VERSION ""

NS_ :

BS_:
BU_:
BO_ 133 GearStatus: 8 Vector__XXX
   SG_ GearPosition : 15|8@0+ (1,0) [0|1] "" Vector__XXX
   SG_ GearStatusSpeed : 39|16@0+ (1,0) [0|1] "" Vector__XXX

BO_ 139 Unknown: 8 Vector__XXX
   SG_ WheelSpeed1 : 7|16@0+ (1,0) [0|1] "" Vector__XXX
   SG_ WheelSpeed2 : 23|16@0+ (1,0) [0|1] "" Vector__XXX
   SG_ WheelSpeed3 : 39|16@0+ (1,0) [0|1] "" Vector__XXX
   SG_ WheelSpeed4 : 55|16@0+ (1,0) [0|1] "" Vector__XXX

BO_ 122 IgnitionSwitch: 4 Vector__XXX
   SG_ IgnitionSwitchPos : 15|8@0+ (1,0) [0|1] "" Vector__XXX

BO_ 1100 Config6: 8 Vector__XXX
   SG_ Config6 : 7|64@0+ (1,0) [0|1] "" Vector__XXX

BO_ 1098 Config5: 8 Vector__XXX
   SG_ Config5 : 7|64@0+ (1,0) [0|1] "" Vector__XXX

BO_ 992 VIN: 8 Vector__XXX
   SG_ VIN : 15|64@4- (1,0) [0|1] "" Vector__XXX
   SG_ VIN_MsgNo : 7|8@0+ (1,0) [0|1] "" Vector__XXX

BO_ 881 SwayBar: 8 Vector__XXX
   SG_ SwayBarDisconnected : 8|1@0+ (1,0) [0|1] "" Vector__XXX
   SG_ SwayBarInProgress : 9|1@0+ (1,0) [0|1] "" Vector__XXX
   SG_ SwayBarLocked : 0|1@0+ (1,0) [0|1] "" Vector__XXX
   SG_ SwayBarPosition : 7|4@0+ (1,0) [0|1] "" Vector__XXX

BO_ 848 DateTime: 8 Vector__XXX
   SG_ DateTimeSeconds : 7|8@0+ (1,0) [0|1] "" Vector__XXX
   SG_ DateTimeMinutes : 15|8@0+ (1,0) [0|1] "" Vector__XXX
   SG_ DateTimeHours : 23|8@0+ (1,0) [0|1] "" Vector__XXX
   SG_ DateTimeYear : 31|16@0+ (1,0) [0|1] "" Vector__XXX
   SG_ DateTimeMonth : 47|8@0+ (1,0) [0|1] "" Vector__XXX
   SG_ DateTimeDay : 55|8@0+ (1,0) [0|1] "" Vector__XXX

BO_ 808 MusicInfo: 8 Vector__XXX

BO_ 662 TirePressure: 8 Vector__XXX
   SG_ TirePressureLF : 31|8@0+ (1,0) [0|1] "psi" Vector__XXX
   SG_ TirePressureRF : 39|8@0+ (1,0) [0|1] "psi" Vector__XXX
   SG_ TirePressureLR : 47|8@0+ (1,0) [0|1] "psi" Vector__XXX
   SG_ TirePressureRR : 55|8@0+ (1,0) [0|1] "psi" Vector__XXX

BO_ 295 Temperatures2: 8 Vector__XXX
   SG_ AmbientPressure : 23|8@0+ (1,0) [0|1] "kPa" Vector__XXX
   SG_ IAT : 7|8@0+ (1,-40) [0|1] "C" Vector__XXX
   SG_ ECT : 15|8@0+ (1,-40) [0|1] "C" Vector__XXX

BO_ 2147483795 GearPosition: 8 Vector__XXX
   SG_ GearPositionSig278 : 23|8@4- (1,0) [0|1] "" Vector__XXX

BO_ 2147484031 GPSSpeed: 8 Vector__XXX
   SG_ GPSSpeed : 55|16@0+ (1,0) [0|1] "" Vector__XXX

BO_ 2147483683 SteeringWheel: 8 Vector__XXX
   SG_ WheelAngle : 7|16@0+ (0.0350877,-144) [0|1] "degrees" Vector__XXX
   SG_ SteeringWheeRateOfChange : 23|16@0+ (1,-4096) [0|1] "" Vector__XXX

BO_ 2147484556 DateTime2: 8 Vector__XXX
   SG_ DateTime2Seconds : 63|8@0+ (1,0) [0|1] "" Vector__XXX

BO_ 2147483691 Accelerometer: 8 Vector__XXX
   SG_ AccelerationLat : 7|16@0+ (1,-2048) [0|1] "" Vector__XXX
   SG_ AccelerationLong : 23|16@0+ (1,-2048) [0|1] "" Vector__XXX
   SG_ YawRate : 39|16@0+ (1,-2048) [0|1] "" Vector__XXX

BO_ 2147483783 Brake: 8 Vector__XXX
   SG_ BrakePressure : 7|16@0+ (1,0) [0|1] "" Vector__XXX

BO_ 2147483769 Brake2: 8 Vector__XXX
   SG_ Brake2Pressure1 : 6|15@0+ (1,0) [0|1] "" Vector__XXX
   SG_ Brake2Pressure2 : 23|16@0+ (1,0) [0|1] "" Vector__XXX
   SG_ Brake2VehicleStopped : 7|1@0+ (1,0) [0|1] "" Vector__XXX

BO_ 2147483779 Speed1: 8 Vector__XXX
   SG_ Speed1Speed : 37|14@0+ (0.5,0) [0|1] "kph" Vector__XXX

BO_ 2147483687 Unknown027: 8 Vector__XXX
   SG_ PossibleMAFFreq : 3|12@0+ (1,0) [0|1] "" Vector__XXX
   SG_ Unknown027Sig3277 : 23|16@0+ (1,-1900) [0|1] "" Vector__XXX

BO_ 2147483793 Constant: 8 Vector__XXX

BO_ 2147483685 Unknown: 8 Vector__XXX
   SG_ Rpm : 7|16@0+ (1,0) [0|1] "" Vector__XXX
   SG_ UnknownRpmRelated : 23|16@0+ (1,0) [0|1] "" Vector__XXX
   SG_ UnknownRpmRelated2 : 39|16@0+ (1,0) [0|1] "" Vector__XXX

BO_ 2147483695 Unknown: 8 Vector__XXX
   SG_ UnknownSig339 : 39|16@0+ (1,0) [0|1] "" Vector__XXX

BO_ 2147483701 Unknown: 8 Vector__XXX
   SG_ UnknownSig93 : 7|16@0- (1,0) [0|1] "" Vector__XXX
   SG_ UnknownSig9343 : 23|16@0+ (1,0) [0|1] "" Vector__XXX
   SG_ UnknownSig934314 : 39|16@0+ (1,0) [0|1] "" Vector__XXX

BO_ 2147483703 Unknown: 8 Vector__XXX
   SG_ UnknownSig278 : 7|16@0+ (1,0) [0|1] "" Vector__XXX
   SG_ UnknownSig27840 : 39|16@0+ (1,0) [0|1] "" Vector__XXX

BO_ 2147483761 Unknown: 8 Vector__XXX
   SG_ UnknownSig297 : 7|16@0+ (1,0) [0|1] "" Vector__XXX

BO_ 2147483767 IgnitionStatus: 2 Vector__XXX
   SG_ IgnitionSwitch : 7|8@0+ (1,0) [0|1] "" Vector__XXX
   SG_ IgnitionState : 15|8@0+ (1,0) [0|1] "" Vector__XXX

BO_ 2147483771 Unknown: 8 Vector__XXX
   SG_ UnknownSig84 : 7|16@0+ (1,0) [0|1] "" Vector__XXX
   SG_ UnknownSig8455 : 23|16@0+ (1,0) [0|1] "" Vector__XXX
   SG_ UnknownSig845598 : 39|16@0+ (1,0) [0|1] "" Vector__XXX

BO_ 2147483777 Unknown: 8 Vector__XXX
   SG_ UnknownSig164 : 23|8@0+ (1,0) [0|1] "" Vector__XXX
   SG_ UnknownSig16496 : 39|8@0+ (1,0) [0|1] "" Vector__XXX
   SG_ UnknownSig1649643 : 47|8@0+ (1,0) [0|1] "" Vector__XXX

BO_ 2147483785 Unknown: 8 Vector__XXX
   SG_ UnknownSig75 : 7|16@0+ (1,0) [0|1] "" Vector__XXX
   SG_ UnknownSig7590 : 23|16@0+ (1,0) [0|1] "" Vector__XXX
   SG_ UnknownSig759080 : 39|16@0+ (1,0) [0|1] "" Vector__XXX

BO_ 2147483797 Unknown: 8 Vector__XXX
   SG_ UnknownSig456 : 7|16@0+ (1,0) [0|1] "" Vector__XXX

BO_ 2147483801 Unknown: 8 Vector__XXX
   SG_ UnknownSig401 : 7|16@0+ (1,0) [0|1] "" Vector__XXX

BO_ 2147483819 Unknown: 8 Vector__XXX
   SG_ UnknownSig131 : 23|8@0+ (1,0) [0|1] "" Vector__XXX
   SG_ UnknownSig13192 : 31|8@0+ (1,0) [0|1] "" Vector__XXX

BO_ 2147483821 Transmission: 4 Vector__XXX
   SG_ TransmissionSig181 : 3|4@0+ (1,0) [0|1] "" Vector__XXX

BO_ 2147483827 Speed: 8 Vector__XXX
   SG_ Speed : 23|16@0+ (1,0) [0|1] "" Vector__XXX
   SG_ UnknownSig46360 : 39|16@0+ (1,0) [0|1] "" Vector__XXX

BO_ 2147483829 Rpm: 8 Vector__XXX
   SG_ Rpm : 23|16@0+ (1,0) [0|1] "" Vector__XXX

BO_ 2147483869 AxleDistance: 8 Vector__XXX
   SG_ DistanceFrontAxle : 7|16@0+ (1,0) [0|1] "" Vector__XXX
   SG_ DistanceRearAxle : 23|16@0+ (1,0) [0|1] "" Vector__XXX

BO_ 2147483953 ECUCode: 8 Vector__XXX

BO_ 2147483965 Unknown: 8 Vector__XXX
   SG_ Temperature : 31|8@0+ (1,0) [0|1] "" Vector__XXX
   SG_ Unknown : 39|16@0+ (1,0) [0|1] "" Vector__XXX

BO_ 2147483971 Empty: 8 Vector__XXX

BO_ 2147483982 Unknown: 8 Vector__XXX
   SG_ UnknownSig15 : 7|16@0+ (1,0) [0|1] "" Vector__XXX

BO_ 2147483989 Empty: 8 Vector__XXX

BO_ 2147483991 Constant: 8 Vector__XXX

BO_ 2147483993 Empty: 8 Vector__XXX

BO_ 2147484096 Constant: 8 Vector__XXX

BO_ 2147484112 Toggle: 8 Vector__XXX

BO_ 2147484117 Constant: 8 Vector__XXX

BO_ 2147484137 Constant: 8 Vector__XXX

BO_ 2147484139 Empty: 8 Vector__XXX

BO_ 2147484150 Constant: 8 Vector__XXX

BO_ 2147484151 Unknown: 8 Vector__XXX
   SG_ SpeedMPHLowRes : 55|16@0+ (1,0) [0|1] "mph" Vector__XXX

BO_ 2147484208 Temperature: 8 Vector__XXX

BO_ 2147484232 Constant: 8 Vector__XXX

BO_ 2147484277 Constant: 8 Vector__XXX

BO_ 2147484249 StartButton: 8 Vector__XXX

BO_ 2147484257 Counter: 8 Vector__XXX

BO_ 2147484261 Constant: 8 Vector__XXX

BO_ 2147484271 SwayBarRequest: 8 Vector__XXX
   SG_ UnknownSig221 : 31|16@0+ (1,0) [0|1] "" Vector__XXX
   SG_ SwayBarRequest : 14|1@0+ (1,0) [0|1] "" Vector__XXX

BO_ 2147484333 Constant: 8 Vector__XXX

BO_ 2147484338 Constant: 8 Vector__XXX

BO_ 2147484357 Constant: 8 Vector__XXX

BO_ 2147484358 Constant: 8 Vector__XXX

BO_ 2147484359 Constant: 8 Vector__XXX

BO_ 2147484360 Constant: 8 Vector__XXX

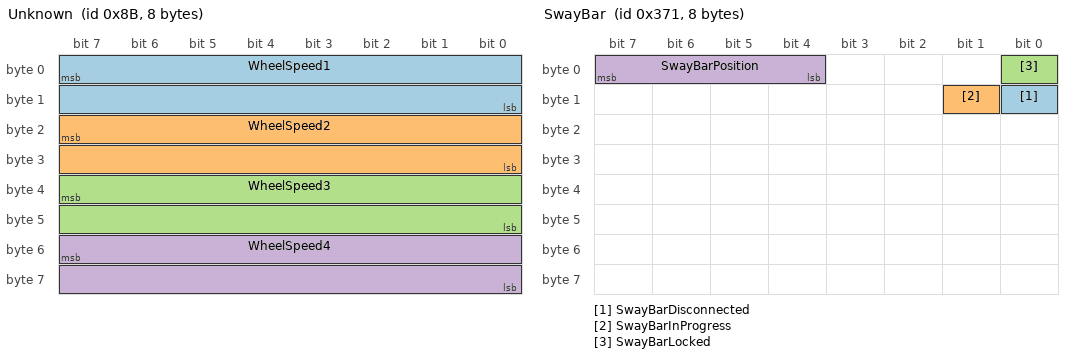
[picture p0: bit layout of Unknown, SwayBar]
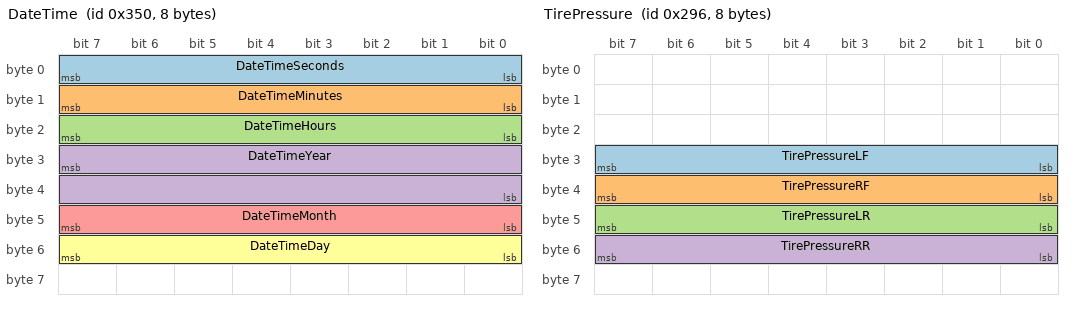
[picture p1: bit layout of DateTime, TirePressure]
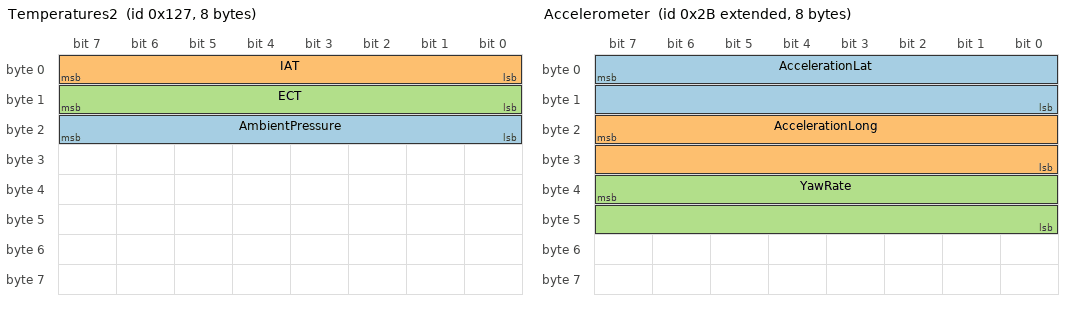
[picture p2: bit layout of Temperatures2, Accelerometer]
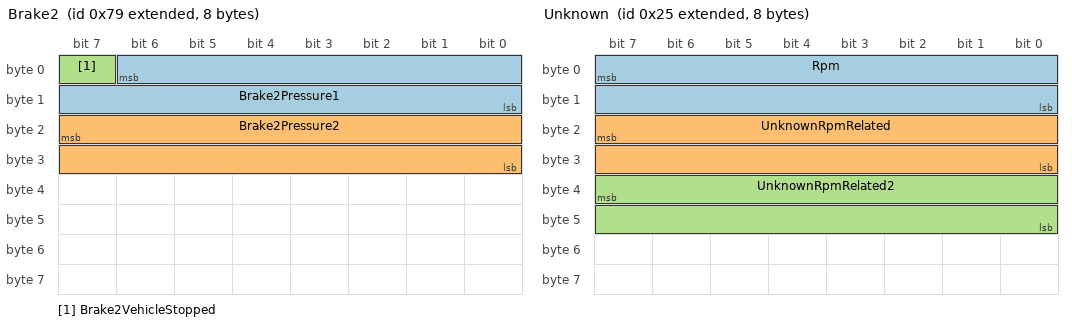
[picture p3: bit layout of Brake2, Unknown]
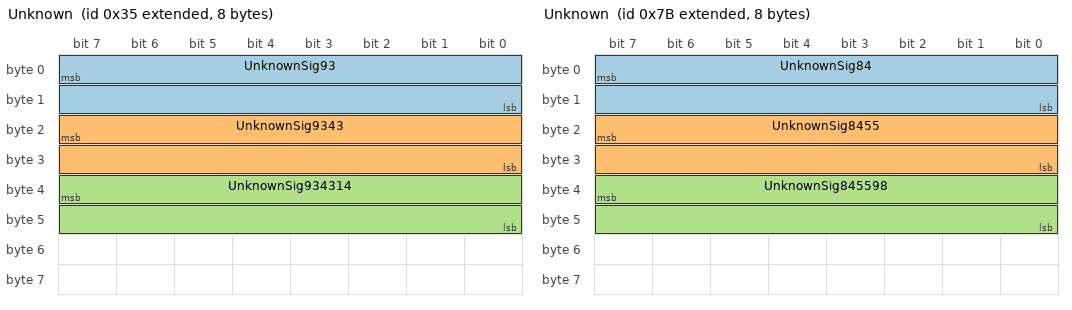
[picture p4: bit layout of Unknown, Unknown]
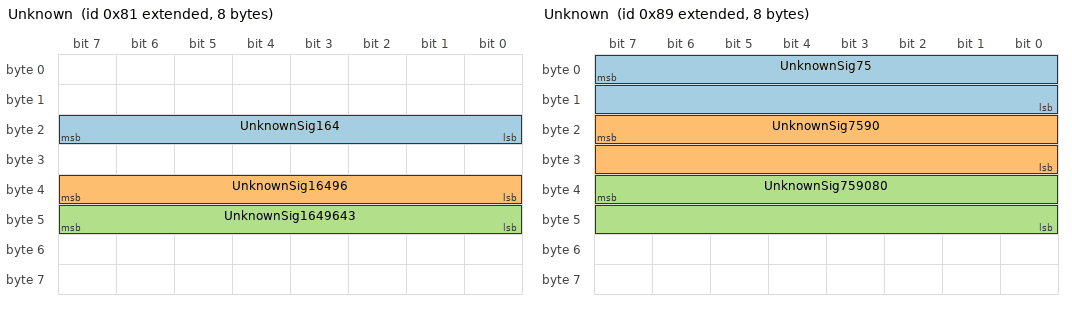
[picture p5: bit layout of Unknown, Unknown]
BO_ 2147484402 Unknown: 8 Vector__XXX
   SG_ UnknownSig448 : 55|16@0+ (1,0) [0|1] "" Vector__XXX

BO_ 2147484441 Empty: 8 Vector__XXX

BO_ 2147484442 Empty: 8 Vector__XXX

BO_ 2147484443 Empty: 8 Vector__XXX

BO_ 2147484449 Empty: 8 Vector__XXX

BO_ 2147484450 Empty: 8 Vector__XXX

BO_ 2147484451 Empty: 8 Vector__XXX

BO_ 2147484466 Constant: 8 Vector__XXX

BO_ 2147484467 Constant: 8 Vector__XXX

BO_ 2147484471 Empty: 8 Vector__XXX

BO_ 2147484508 Constant: 6 Vector__XXX

BO_ 2147484534 NaviFlags: 6 Vector__XXX
   SG_ Flag1 : 23|8@0+ (1,0) [0|1] "" Vector__XXX
   SG_ NextTurnDistance : 31|16@0+ (0.1,0) [0|1] "" Vector__XXX
   SG_ Flag2 : 43|4@0+ (1,0) [0|1] "" Vector__XXX
   SG_ Flag3 : 55|4@0+ (1,0) [0|1] "" Vector__XXX

BO_ 2147484545 Constant: 6 Vector__XXX

BO_ 2147484554 Constant: 6 Vector__XXX

BO_ 2147484557 Constant: 8 Vector__XXX

BO_ 2147484585 Constant: 8 Vector__XXX

BO_ 2147484587 Constant: 8 Vector__XXX

BO_ 2147484595 Constant: 8 Vector__XXX

BO_ 2147484596 Constant: 8 Vector__XXX

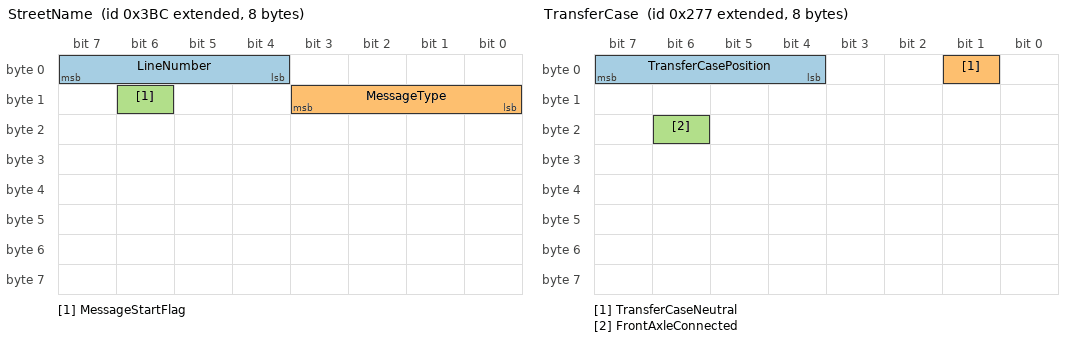
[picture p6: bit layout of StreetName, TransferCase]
BO_ 2147484604 StreetName: 8 Vector__XXX
   SG_ LineNumber : 7|4@0+ (1,0) [0|1] "" Vector__XXX
   SG_ MessageType : 11|4@0+ (1,0) [0|1] "" Vector__XXX
   SG_ MessageStartFlag : 14|1@0+ (1,0) [0|1] "" Vector__XXX
   SG_ MessageData : 31|40@4- (1,0) [0|1] "" Vector__XXX

BO_ 2147484606 Empty: 8 Vector__XXX

BO_ 2147484607 Empty: 8 Vector__XXX

BO_ 2147484610 Constant: 8 Vector__XXX

BO_ 2147484614 Constant: 8 Vector__XXX

BO_ 2147484624 Empty: 8 Vector__XXX

BO_ 2147484627 Constant: 8 Vector__XXX

BO_ 2147484628 Constant: 8 Vector__XXX

BO_ 2147484629 Constant: 8 Vector__XXX

BO_ 2147484630 Constant: 8 Vector__XXX

BO_ 2147484631 Constant: 8 Vector__XXX

BO_ 2147484632 Constant: 8 Vector__XXX

BO_ 2147484641 Constant: 8 Vector__XXX

BO_ 2147484643 Constant: 8 Vector__XXX

BO_ 2147485664 PowertrainModuleRx: 8 Vector__XXX

BO_ 2147485672 PowertrainModuleTx: 8 Vector__XXX

BO_ 2147484253 AxleLocker: 8 Vector__XXX
   SG_ AxleLockerRequest : 6|2@0+ (1,0) [0|1] "" Vector__XXX

BO_ 2147484279 TransferCase: 8 Vector__XXX
   SG_ TransferCasePosition : 7|4@0+ (1,0) [0|1] "" Vector__XXX
   SG_ TransferCaseNeutral : 1|1@0+ (1,0) [0|1] "" Vector__XXX
   SG_ FrontAxleConnected : 22|1@0+ (1,0) [0|1] "" Vector__XXX

BO_ 2147484440 SteeringWheelButtons: 8 Vector__XXX

BO_ 2147485515 DriveTrainModuleTx: 8 Vector__XXX

BO_ 2147485511 ABSModuleTx: 8 Vector__XXX

BO_ 2147484875 DriveTrainModuleRx: 8 Vector__XXX

BO_ 2147484871 ABSModuleRx: 8 Vector__XXX

BO_ 2147484110 KeyFob: 8 Vector__XXX
   SG_ KeyFobSignal : 7|8@0+ (1,0) [0|1] "" Vector__XXX

BO_ 2147483803 Interiror: 8 Vector__XXX
   SG_ DriverDoorClosed : 42|1@0+ (1,0) [0|1] "" Vector__XXX

BO_ 2147483941 TransTemp: 8 Vector__XXX
   SG_ TransTemp : 15|8@0+ (1,0) [0|1] "" Vector__XXX

BO_ 2147485216 BCMTx: 8 Vector__XXX

BO_ 2147484932 BCMRx: 8 Vector__XXX

BO_ 2147485504 RFHubTx: 8 Vector__XXX

BO_ 2147484864 RfHubRx: 8 Vector__XXX

BO_ 2147484866 IPPanelRx: 8 Vector__XXX

BO_ 2147484867 TPMSRx: 8 Vector__XXX

BO_ 2147484868 AirbagsRx: 8 Vector__XXX

BO_ 2147484873 ShifterRx: 8 Vector__XXX

BO_ 2147484881 DriverPresenceRx: 8 Vector__XXX

BO_ 2147484883 ACCRx: 8 Vector__XXX

BO_ 2147484890 EPSRx: 8 Vector__XXX

BO_ 2147484898 ParkAssistRx: 8 Vector__XXX

BO_ 2147484899 SteeringColumnRx: 8 Vector__XXX

BO_ 2147484971 AssistanceRx: 8 Vector__XXX

BO_ 2147484988 CenterStackRx: 8 Vector__XXX

BO_ 2147485665 TCMRx: 8 Vector__XXX

BO_ 2147485673 TCMTx: 8 Vector__XXX

BO_ 2147485628 CenterStackTx: 8 Vector__XXX

BO_ 2147485611 AssistanceTx: 8 Vector__XXX

BO_ 2147485506 IPPanelTx: 8 Vector__XXX

BO_ 2147485507 TPMSTx: 8 Vector__XXX

BO_ 2147485508 AirbagsTx: 8 Vector__XXX

BO_ 2147485513 ShifterTx: 8 Vector__XXX

BO_ 2147485521 DriverPresenceTx: 8 Vector__XXX

BO_ 2147485523 ACCTx: 8 Vector__XXX

BO_ 2147485530 EPSTx: 8 Vector__XXX

BO_ 2147485538 ParkAssistTx: 8 Vector__XXX

BO_ 2147485539 SteeringColumnTx: 8 Vector__XXX

CM_ BO_ 139 "transmission";
BA_DEF_ BO_ "GenMsgBackgroundColor" STRING ;
BA_DEF_ BO_ "GenMsgForegroundColor" STRING ;
BA_DEF_ BO_ "filterlabeling" INT 0 0;
BA_DEF_ BO_ "filterlabeling" INT 0 0;
BA_DEF_ BO_ "filterlabeling" INT 0 0;
BA_DEF_ BO_ "filterlabeling" INT 0 0;
BA_DEF_ BO_ "filterlabeling" INT 0 0;
BA_DEF_ BO_ "filterlabeling" INT 0 0;
BA_DEF_ BO_ "filterlabeling" INT 0 0;
BA_DEF_ BO_ "filterlabeling" INT 0 0;
BA_DEF_ BO_ "filterlabeling" INT 0 0;
BA_DEF_ BO_ "filterlabeling" INT 0 0;
BA_DEF_ BO_ "filterlabeling" INT 0 0;
BA_DEF_ BO_ "filterlabeling" INT 0 0;
BA_DEF_ BO_ "filterlabeling" INT 0 0;
BA_DEF_ BO_ "filterlabeling" INT 0 0;
BA_DEF_ BO_ "filterlabeling" INT 0 0;
BA_DEF_ BO_ "filterlabeling" INT 0 0;
BA_DEF_ BO_ "filterlabeling" INT 0 0;
BA_DEF_ BO_ "filterlabeling" INT 0 0;
BA_DEF_ BO_ "filterlabeling" INT 0 0;
BA_DEF_ BO_ "filterlabeling" INT 0 0;
BA_DEF_ BO_ "filterlabeling" INT 0 0;
BA_DEF_ BO_ "filterlabeling" INT 0 0;
BA_DEF_ BO_ "filterlabeling" INT 0 0;
BA_DEF_ BO_ "filterlabeling" INT 0 0;
BA_DEF_ BO_ "filterlabeling" INT 0 0;
BA_DEF_ BO_ "filterlabeling" INT 0 0;
BA_DEF_ BO_ "filterlabeling" INT 0 0;
BA_DEF_DEF_ "GenMsgBackgroundColor" "#ffffff";
BA_DEF_DEF_ "GenMsgForegroundColor" "#000000";
BA_DEF_DEF_ "filterlabeling" 1;
BA_DEF_DEF_ "filterlabeling" 1;
BA_ "GenMsgBackgroundColor" BO_ 808 "#55ff7f";
VAL_ 2147483821 TransmissionSig181 1 "Park" 4 "Drive";
